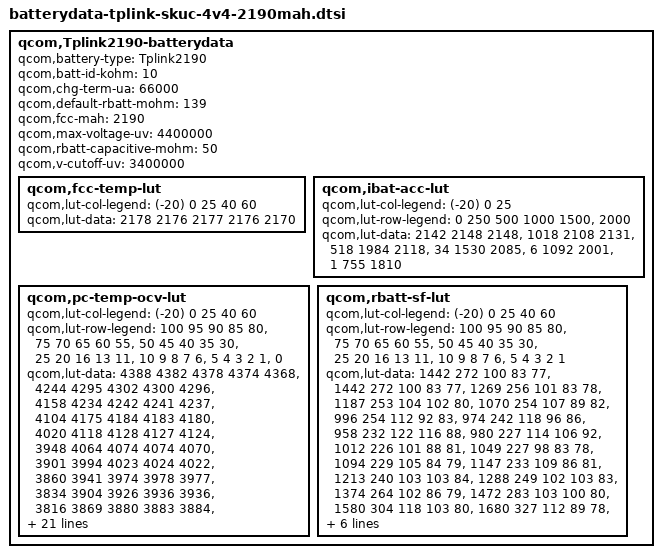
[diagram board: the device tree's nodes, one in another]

qcom,Tplink2190-batterydata {
	qcom,battery-type = "Tplink2190";
	qcom,batt-id-kohm = <10>;
	qcom,chg-term-ua = <66000>;
	qcom,default-rbatt-mohm = <139>;
	qcom,fcc-mah = <2190>;
	qcom,max-voltage-uv = <4400000>;
	qcom,rbatt-capacitive-mohm = <50>;
	qcom,v-cutoff-uv = <3400000>;

	qcom,fcc-temp-lut {
		qcom,lut-col-legend = <(-20) 0 25 40 60>;
		qcom,lut-data = <2178 2176 2177 2176 2170>;
	};

	qcom,ibat-acc-lut {
		qcom,lut-col-legend = <(-20) 0 25>;
		qcom,lut-row-legend = <0 250 500 1000 1500>,
					<2000>;
		qcom,lut-data = <2142 2148 2148>,
				<1018 2108 2131>,
				<518 1984 2118>,
				<34 1530 2085>,
				<6 1092 2001>,
				<1 755 1810>;
	};

	qcom,pc-temp-ocv-lut {
		qcom,lut-col-legend = <(-20) 0 25 40 60>;
		qcom,lut-row-legend = <100 95 90 85 80>,
					<75 70 65 60 55>,
					<50 45 40 35 30>,
					<25 20 16 13 11>,
					<10 9 8 7 6>,
					<5 4 3 2 1>,
					<0>;
		qcom,lut-data = <4388 4382 4378 4374 4368>,
				<4244 4295 4302 4300 4296>,
				<4158 4234 4242 4241 4237>,
				<4104 4175 4184 4183 4180>,
				<4020 4118 4128 4127 4124>,
				<3948 4064 4074 4074 4070>,
				<3901 3994 4023 4024 4022>,
				<3860 3941 3974 3978 3977>,
				<3834 3904 3926 3936 3936>,
				<3816 3869 3880 3883 3884>,
				<3800 3838 3848 3848 3849>,
				<3786 3812 3822 3824 3823>,
				<3772 3792 3801 3802 3802>,
				<3758 3776 3784 3786 3785>,
				<3742 3764 3768 3768 3766>,
				<3726 3752 3755 3750 3740>,
				<3705 3734 3738 3731 3718>,
				<3685 3717 3719 3712 3698>,
				<3668 3703 3700 3692 3680>,
				<3653 3694 3689 3683 3672>,
				<3646 3690 3686 3680 3670>,
				<3637 3686 3684 3679 3668>,
				<3626 3682 3683 3677 3665>,
				<3612 3676 3680 3674 3662>,
				<3594 3667 3672 3666 3652>,
				<3570 3648 3654 3645 3626>,
				<3540 3613 3613 3602 3580>,
				<3498 3559 3554 3542 3518>,
				<3432 3480 3472 3460 3435>,
				<3310 3352 3344 3331 3304>,
				<3000 3000 3000 3000 3000>;
	};

	qcom,rbatt-sf-lut {
		qcom,lut-col-legend = <(-20) 0 25 40 60>;
		qcom,lut-row-legend = <100 95 90 85 80>,
					<75 70 65 60 55>,
					<50 45 40 35 30>,
					<25 20 16 13 11>,
					<10 9 8 7 6>,
					<5 4 3 2 1>;
		qcom,lut-data = <1442 272 100 83 77>,
				<1442 272 100 83 77>,
				<1269 256 101 83 78>,
				<1187 253 104 102 80>,
				<1070 254 107 89 82>,
				<996 254 112 92 83>,
				<974 242 118 96 86>,
				<958 232 122 116 88>,
				<980 227 114 106 92>,
				<1012 226 101 88 81>,
				<1049 227 98 83 78>,
				<1094 229 105 84 79>,
				<1147 233 109 86 81>,
				<1213 240 103 103 84>,
				<1288 249 102 103 83>,
				<1374 264 102 86 79>,
				<1472 283 103 100 80>,
				<1580 304 118 103 80>,
				<1680 327 112 89 78>,
				<1754 348 106 97 79>,
				<1769 357 105 95 81>,
				<1794 364 106 90 82>,
				<1915 386 111 93 85>,
				<2157 413 115 96 88>,
				<2486 448 119 99 91>,
				<2957 489 119 103 84>,
				<3653 543 114 106 84>,
				<4826 642 117 101 85>,
				<6951 844 124 98 88>,
				<12529 1465 164 149 145>;
	};
};
/* TEST_DB_ID=TEST_ID_NOT_SET */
